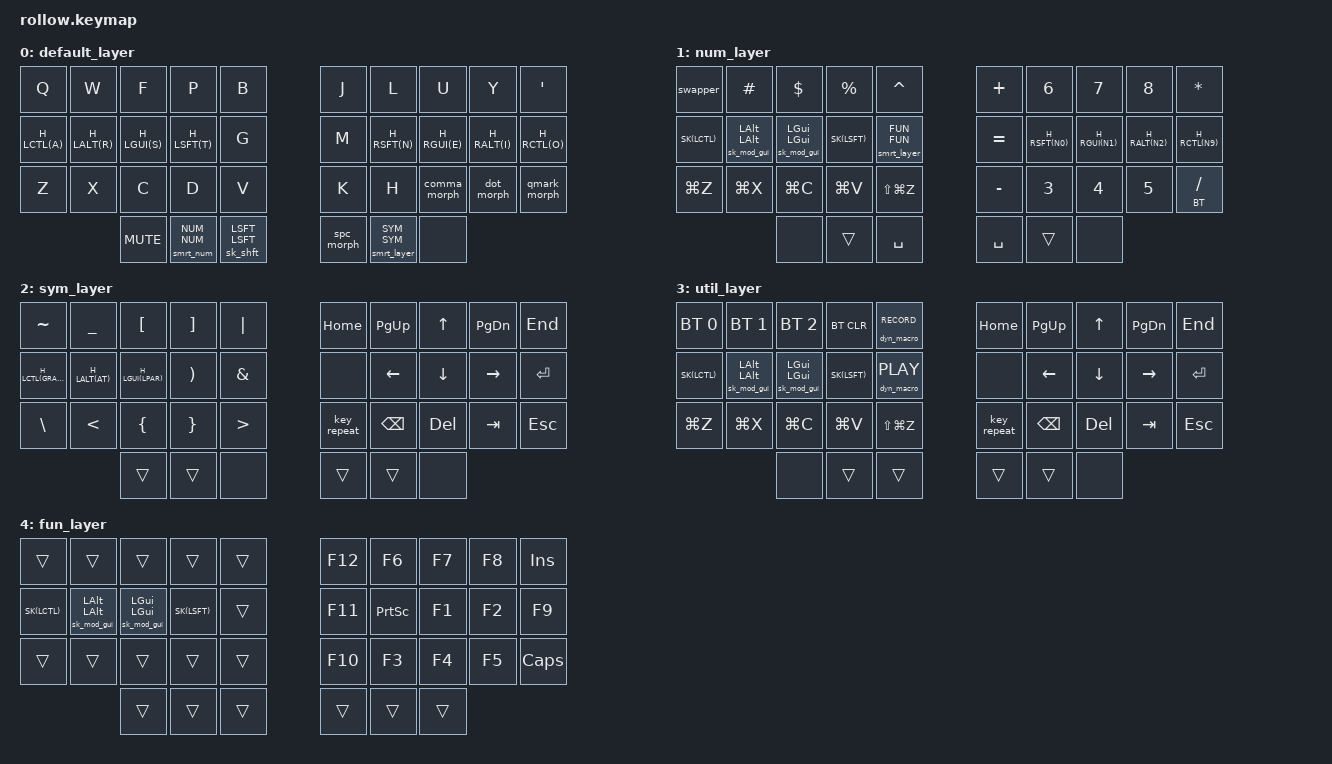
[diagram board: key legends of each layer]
// Copyright (c) 2022 The ZMK Contributors
// SPDX-License-Identifier: MIT

#include "../zmk-nodefree-config/helper.h"
#include "../zmk-nodefree-config/keypos_def/keypos_36keys.h"
#include <behaviors.dtsi>
#include <dt-bindings/zmk/keys.h>
#include <dt-bindings/zmk/bt.h>
#include <dt-bindings/zmk/dynamic-macros.h>

#define XXX &none
#define TODO XXX
#define ___ &trans

#define BASE 0
#define NUM 1
#define SYM 2
#define UTIL 3
#define FUN 4
#define BT 5

#define S_UNDO &kp LG(Z)
#define S_CUT &kp LG(X)
#define S_COPY &kp LG(C)
#define S_PASTE &kp LG(V)
#define S_REDO &kp LS(LG(Z))

/* ------------------------ general config ----------------------- */
// smart-layer config
&caps_word {  
    /delete-property/ ignore-modifiers; // mods deactivate, requires PR #1451
    /delete-property/ ignore-numbers;
    continue-list = <BACKSPACE ENTER DELETE UNDERSCORE MINUS>;
};
&num_word { 
    layers = <NUM>; // requires PR #1441
    continue-list = <BACKSPACE ENTER DELETE UNDERSCORE MINUS PLUS ASTRK EQUAL FSLH DOT LPAR RPAR HASH DLLR PRCNT CARET LEFT RIGHT UP DOWN>;
};

// key-repeat config
&key_repeat {
    usage-pages = <HID_USAGE_KEY HID_USAGE_CONSUMER>; // repeat all keys
};

// default layer-tap config
&lt {  
    flavor = "balanced";
    tapping-term-ms = <200>;
};

ZMK_CONDITIONAL_LAYER(NUM SYM, UTIL)

/* ---------------------------- special behaviors --------------------------- */
// Alt+Tab swapper, requires PR #1366
ZMK_BEHAVIOR(swapper, tri_state,
    bindings = <&kt LALT>, <&kp TAB>, <&kt LGUI>;
    ignored-key-positions = <LM1>; // shift-alt-tab 
)

// dynamci macros, requires PR #1351
ZMK_BEHAVIOR(dyn_macro, dynamic_macro, wait-ms = <10>;)

/* ------------------------------ home row mods ----------------------------- */
// #define KEYS_L LT0 LT1 LT2 LT3 LT4 LM0 LM1 LM2 LM3 LM4 LB0 LB1 LB2 LB3 LB4  // left hand
// #define KEYS_R RT0 RT1 RT2 RT3 RT4 RM0 RM1 RM2 RM3 RM4 RB0 RB1 RB2 RB3 RB4  // right hand
// #define THUMBS LH2 LH1 LH0 RH0 RH1 RH2                                      // thumbs

// // 280, 150
// #define MAKE_HRM(NAME, HOLD, TAP, TRIGGER_POS, EXTRA) \
//     ZMK_BEHAVIOR(NAME, hold_tap, \
//         flavor = "balanced"; \
//         tapping-term-ms = <500>; \
//         quick-tap-ms = <175>; \
//         global-quick-tap-ms = <150>; \
//         bindings = <HOLD>, <TAP>; \
//         hold-trigger-key-positions = <TRIGGER_POS>; \
//         hold-trigger-on-release; \
//         EXTRA \
//     )
// // TODO: potentially only space thumb
// MAKE_HRM(hmlg, &kp, &kp, KEYS_R THUMBS, )  // left-hand HRMs
// MAKE_HRM(hmrg, &kp, &kp, KEYS_L THUMBS, )  // right-hand HRMs
// MAKE_HRM(hml, &kp, &kp, KEYS_R THUMBS, hold-while-undecided;)  // left-hand HRMs
// MAKE_HRM(hmr, &kp, &kp, KEYS_L THUMBS, hold-while-undecided;)  // right-hand HRMs

#define H_LGUI(key) &kp key
#define H_LALT(key) &kp key
#define H_LCTL(key) &kp key
#define H_LSFT(key) &kp key
#define H_RSFT(key) &kp key
#define H_RCTL(key) &kp key
#define H_RALT(key) &kp key
#define H_RGUI(key) &kp key
// #define H_LGUI(key) &hmlg LGUI key 
// #define H_LALT(key) &hmlg LALT key 
// #define H_LCTL(key) &hml LCTL key
// #define H_LSFT(key) &hml LSFT key
// #define H_RSFT(key) &hmr RSFT key
// #define H_RCTL(key) &hmr RCTL key
// #define H_RALT(key) &hmrg RALT key
// #define H_RGUI(key) &hmrg RGUI key

/* --------------------------- sticky key behaviors -------------------------- */
// global config
&sk { // sticky-key
    release-after-ms = <3000>;  // release after timeout
    quick-release;              // no double capitalization when rolling ke
    ignore-modifiers;
    lazy;
};
ZMK_BEHAVIOR(sk_no_lazy, sticky_key, // sticky-key without lazy
    bindings = <&kp>;
    release-after-ms = <3000>;  // release after timeout
    quick-release;              // no double capitalization when rolling keys
    ignore-modifiers;
)
&sl { // sticky-layer 
    release-after-ms = <500>;  // release after timeout
    // This is useful for enabling a layer and then pressing a bunch of sticky keys without leaving the layer. 
    // However, this breaks tapping sl+control+key because it does not exit the layer.
    // ignore-modifiers;
};

// all sticky keys are sticky when tapped, but momentary when held. 
// this allows for rolling layer keys, and accessing modifiers on base, while not getting in the way.
// this behavior is especially useful for use with a mouse because sticky odifiers don't linger
#define STICKY_TAP_MS 200

// tap: sticky-mod | hold: mod
#define SK(mod) &sk_mod mod mod
ZMK_BEHAVIOR(sk_mod, hold_tap,
    flavor = "balanced"; // balanced because we want to consider as tap when rolling
    tapping-term-ms = <STICKY_TAP_MS>; 
    bindings = <&kp>, <&sk>; 
    hold-while-undecided; // requires pr
)
// for GUI/ALT, we don't want to trigger a tap, so we disable hold while undecided
#define SK_LGUI &sk_mod_gui LGUI LGUI 
#define SK_LALT &sk_mod_gui LALT LALT 
ZMK_BEHAVIOR(sk_mod_gui, hold_tap,
    flavor = "balanced"; // balanced because we want to consider as tap when rolling
    tapping-term-ms = <STICKY_TAP_MS>; 
    bindings = <&kp>, <&sk>; 
)

// tap: sticky-shift | hold: shift | shift + tap / double-tap: caps-word 
#define SK_SHFT &sk_shft LSFT LSFT
ZMK_BEHAVIOR(sk_shft, hold_tap,
    flavor = "balanced"; 
    tapping-term-ms = <STICKY_TAP_MS>; 
    bindings = <&kp>, <&smrt_shft_morph>; 
    hold-while-undecided;
) 
ZMK_BEHAVIOR(smrt_shft_morph, mod_morph,
    mods = <(MOD_LSFT)>; // shift + tap: caps word
    bindings = <&sk_no_lazy LSFT>, <&caps_word>; 
) 

// tap: sticky-layer | hold: layer
#define SMRT_SYM &smrt_layer SYM SYM
#define SMRT_FUN &smrt_layer FUN FUN
ZMK_BEHAVIOR(smrt_layer, hold_tap,
    flavor = "hold-preferred"; // in most cases we want to avoid taps
    tapping-term-ms = <STICKY_TAP_MS>; 
    bindings = <&mo>, <&sl>; 
) 

// tap: sticky-num | hold: num | double-tap: num-word | triple-tap: num-lock
#define SMRT_NUM &smrt_num NUM NUM
ZMK_BEHAVIOR(smrt_num, hold_tap,
    flavor = "hold-preferred"; 
    tapping-term-ms = <STICKY_TAP_MS>; 
    bindings = <&mo>, <&num_dance>; 
) 
ZMK_BEHAVIOR(num_dance, tap_dance,
    tapping-term-ms = <300>; 
    bindings = <&sl NUM>, <&num_word>, <&tog NUM>; // todo: to or tog?
)

/* ------------------------------- mod-morphs ------------------------------- */
// tap: comma | shift + tap: semicolon 
ZMK_BEHAVIOR(comma_morph, mod_morph,
    mods = <(MOD_LSFT|MOD_RSFT)>;
    bindings = <&kp COMMA>, <&kp SEMICOLON>;
)
// tap: dot | shift + tap: colon 
ZMK_BEHAVIOR(dot_morph, mod_morph,
    bindings = <&kp DOT>, <&kp COLON>;
    mods = <(MOD_LSFT|MOD_RSFT)>;
)
// tap: qmark | shift + tap: excl
ZMK_BEHAVIOR(qmark_morph, mod_morph,
    bindings = <&kp QMARK>, <&kp EXCL>;
    mods = <(MOD_LSFT|MOD_RSFT)>;
)

// tap: space | shift + tap: dot -> space -> sticky shift
ZMK_BEHAVIOR(spc_morph, mod_morph,
    bindings = <&kp SPACE>, <&dot_spc>;
    mods = <(MOD_LSFT|MOD_RSFT)>;
)
ZMK_BEHAVIOR(dot_spc, macro,
    wait-ms = <5>;
    tap-ms = <5>;
    bindings = <&dot_morph_cancel &kp SPACE &sk LSFT>;
)
ZMK_BEHAVIOR(dot_morph_cancel, mod_morph,
    bindings = <&kp DOT>, <&kp DOT>;
    mods = <(MOD_LSFT|MOD_RSFT)>;
)

/ {
    chosen {
        zmk,matrix_transform = &five_column_transform;
    };

    keymap {
        compatible = "zmk,keymap";
        default_layer { // ColemakDHm
            bindings = <
            &kp Q     &kp W     &kp F     &kp P     &kp B     &kp J       &kp L     &kp U        &kp Y      &kp APOS 
            H_LCTL(A) H_LALT(R) H_LGUI(S) H_LSFT(T) &kp G     &kp M       H_RSFT(N) H_RGUI(E)    H_RALT(I)  H_RCTL(O) 
            &kp Z     &kp X     &kp C     &kp D     &kp V     &kp K       &kp H     &comma_morph &dot_morph &qmark_morph
                                &kp C_MUTE SMRT_NUM SK_SHFT   &spc_morph  SMRT_SYM  XXX 
            >;
        };
        num_layer {
            bindings = <
            &swapper  &kp HASH  &kp DLLR   &kp PRCNT  &kp CARET   &kp PLUS  &kp N6     &kp N7     &kp N8     &kp ASTRK 
            SK(LCTL)   SK_LALT   SK_LGUI   SK(LSFT)   SMRT_FUN    &kp EQUAL H_RSFT(N0) H_RGUI(N1) H_RALT(N2) H_RCTL(N9) 
            S_UNDO    S_CUT     S_COPY     S_PASTE    S_REDO      &kp MINUS &kp N3     &kp N4     &kp N5     &lt BT FSLH 
                                XXX        ___        &kp SPACE   &kp SPACE ___        XXX 
            >;
        };
        sym_layer {
            bindings = <
            &kp TILDE     &kp UNDER   &kp LBKT      &kp RBKT  &kp PIPE      &kp HOME    &kp PG_UP  &kp UP     &kp PG_DN  &kp END
            H_LCTL(GRAVE) H_LALT(AT)  H_LGUI(LPAR)  &kp RPAR  &kp AMPS      XXX         &kp LEFT   &kp DOWN   &kp RIGHT  &kp ENTER 
            &kp BSLH      &kp LT      &kp LBRC      &kp RBRC  &kp GT        &key_repeat &kp BSPC   &kp DEL    &kp TAB    &kp ESC 
                                      ___           ___       XXX           ___         ___        XXX 
            >;
        };
 
        util_layer {
            bindings = <
            &bt BT_SEL 0 &bt BT_SEL 1 &bt BT_SEL 2 &bt BT_CLR  &dyn_macro RECORD  &kp HOME     &kp PG_UP  &kp UP    &kp PG_DN  &kp END
            SK(LCTL)      SK_LALT      SK_LGUI     SK(LSFT)    &dyn_macro PLAY    XXX          &kp LEFT   &kp DOWN  &kp RIGHT  &kp ENTER 
            S_UNDO       S_CUT        S_COPY       S_PASTE     S_REDO             &key_repeat  &kp BSPC   &kp DEL   &kp TAB    &kp ESC 
                                      XXX          ___         ___                ___          ___        XXX 
            >;
        };

        fun_layer {
            bindings = <
            ___       ___       ___        ___        ___    &kp F12  &kp F6     &kp F7  &kp F8  &kp INSERT
            SK(LCTL)   SK_LALT   SK_LGUI   SK(LSFT)   ___    &kp F11  &kp PSCRN  &kp F1  &kp F2  &kp F9
            ___       ___       ___        ___        ___    &kp F10  &kp F3     &kp F4  &kp F5  &kp CAPS
                                ___        ___        ___    ___      ___        ___ 
            >;
        };
    };
};
    
/* --------------------------------- combos --------------------------------- */
// ╭─────────────────────┬─────────────────────╮
// │ LT4 LT3 LT2 LT1 LT0 │ RT0 RT1 RT2 RT3 RT4 │
// │ LM4 LM3 LM2 LM1 LM0 │ RM0 RM1 RM2 RM3 RM4 │
// │ LB4 LB3 LB2 LB1 LB0 │ RB0 RB1 RB2 RB3 RB4 │
// ╰───────╮ LH2 LH1 LH0 │ RH0 RH1 RH2 ╭───────╯
//         ╰─────────────┴─────────────╯
// use global-quick-tap-ms for combos (requires PR 1387)
#undef COMBO_HOOK
#define COMBO_HOOK global-quick-tap-ms = <50>;
// combos on every layer
#define LAYER_COMBO(name, keypos, bindings, layer) ZMK_COMBO(name, bindings, keypos, layer, 50)
#define GLOBAL_COMBO(name, keypos, bindings) LAYER_COMBO(name, keypos, bindings, ALL)
// GLOBAL_COMBO(bksp, RB1 RB2, &kp BSPC)
// GLOBAL_COMBO(del, RB2 RB3, &kp DEL)
GLOBAL_COMBO(numl, RB3 RB4, &num_word)
GLOBAL_COMBO(dot_spc, LH0 RH0, &dot_spc)

// combos on the numpad
#define NUM_COMBO(name, keypos, bindings) ZMK_COMBO(name, bindings, keypos, NUM, 40)
NUM_COMBO(dot, RM0 RM1, &kp DOT)
NUM_COMBO(esc, LT3 LT2, &kp ESC)
NUM_COMBO(tab, LT2 LT1, &kp TAB)
NUM_COMBO(gui, LB3 LB2, &kp LGUI)
NUM_COMBO(ent, LB2 LB1, &kp ENTER)
NUM_COMBO(lpar, LT2 LM2, &kp LPAR)
NUM_COMBO(rpar, LT1 LM1, &kp RPAR)
NUM_COMBO(x, LM3 LB3, &kp X)

// vertical sfb combos
#define VERTICAL_COMBO(keypos, key1, key2) \
    ZMK_BEHAVIOR(macro_vertical_combo_##key1##key2, macro, \
        wait-ms = <20>; \
        tap-ms = <20>; \
        bindings \
            = <&macro_tap &kp key1> \
            , <&macro_press &kp key2> \
            , <&macro_pause_for_release> \
            , <&macro_release &kp key2> \
            ; \
    ) \
    / { \
        combos { \
            compatible = "zmk,combos"; \
            combo_vertical_combo_##key1##key2 { \
                timeout-ms = <40>; \
                layers = <BASE>; \
                key-positions = <keypos>; \
                bindings = <&macro_vertical_combo_##key1##key2>; \
                slow-release;  \
            }; \
        }; \
    };

// disambiguate mashing SFBs
// this is the only one relevant to Colemak layout
/* VERTICAL_COMBO(LT3 LM3, R, L) */
/* VERTICAL_COMBO(LT1 LM1, W, S) */
VERTICAL_COMBO(LM2 LB2, S, C)
/* VERTICAL_COMBO(LM1 LM0, G, S) */
/* VERTICAL_COMBO(RM1 RM0, H, Y) */
/* VERTICAL_COMBO(RM1 RB1, P, H) */
/* VERTICAL_COMBO(RT2 RM2, O, A) */
/* VERTICAL_COMBO(RM0 RT0, Y, APOS) */
/* VERTICAL_COMBO(RM4 RT0, I, APOS) */

// ANACRON COMBOS
// the macro is used to enable the layer while the combo is held so that other keys
// on the layer can be used while the thumb is still held
#define THUMB_COMBO_GENERAL(thumb_behavior, thumb_param, thumb, combo_layers, keypos, combo_bindings) \
    ZMK_BEHAVIOR(macro_thumb_##thumb_param##_##thumb##_##keypos, macro, \
        wait-ms = <0>; \
        tap-ms = <0>; \
        bindings \
            = <&macro_press thumb_behavior thumb_param> \
            , <&macro_press combo_bindings> \
            , <&macro_pause_for_release> \
            , <&macro_release combo_bindings> \
            , <&macro_release thumb_behavior thumb_param> \
            ; \
    ) \
    / { \
        combos { \
            compatible = "zmk,combos"; \
            combo_thumb_##thumb_param##_##thumb##_##keypos { \
                timeout-ms = <40>; \
                layers = <combo_layers>; \
                key-positions = <thumb keypos>; \
                bindings = <&macro_thumb_##thumb_param##_##thumb##_##keypos>, <&partial_hold_position thumb thumb_behavior thumb_param>; \
                slow-release;  \
                slow-release-positions = <keypos>; \
                COMBO_HOOK \
            }; \
        }; \
    };
#define THUMB_LAYER_COMBO(thumb_param, thumb, combo_layers, keypos, combo_bindings) THUMB_COMBO_GENERAL(&mo, thumb_param, thumb, combo_layers, keypos, combo_bindings)

// right thumb combos with right hand SYM layer
#define SYM_THUMB_COMBO(keypos, bindings) THUMB_LAYER_COMBO(SYM, RH1, BASE NUM, keypos, bindings)
SYM_THUMB_COMBO(RT0, &kp HOME)
SYM_THUMB_COMBO(RT1, &kp PG_UP)
SYM_THUMB_COMBO(RT2, &kp UP)
SYM_THUMB_COMBO(RT3, &kp PG_DN)
SYM_THUMB_COMBO(RT4, &kp END)
//SYM_THUMB_COMBO(RM0, XXX)
SYM_THUMB_COMBO(RM1, &kp LEFT)
SYM_THUMB_COMBO(RM2, &kp DOWN)
SYM_THUMB_COMBO(RM3, &kp RIGHT)
SYM_THUMB_COMBO(RM4, &kp ENTER)
SYM_THUMB_COMBO(RB0, &key_repeat) 
SYM_THUMB_COMBO(RB1, &kp BSPC)
SYM_THUMB_COMBO(RB2, &kp DEL)
SYM_THUMB_COMBO(RB3, &kp TAB)
SYM_THUMB_COMBO(RB4, &kp ESC)

// right thumb combos with left hand SYM layer 
#define SYM_THUMB_CROSS_COMBO(keypos, bindings) THUMB_LAYER_COMBO(SYM, RH1, BASE, keypos, bindings)
SYM_THUMB_CROSS_COMBO(LT4, &kp TILDE)
SYM_THUMB_CROSS_COMBO(LT3, &kp PIPE)
SYM_THUMB_CROSS_COMBO(LT2, &kp UNDER)
SYM_THUMB_CROSS_COMBO(LT1, &kp LBKT)
SYM_THUMB_CROSS_COMBO(LT0, &kp RBKT)
SYM_THUMB_CROSS_COMBO(LM4, &kp GRAVE)
SYM_THUMB_CROSS_COMBO(LM3, &kp AMPS)
SYM_THUMB_CROSS_COMBO(LM2, &kp AT)
SYM_THUMB_CROSS_COMBO(LM1, &kp LPAR)
SYM_THUMB_CROSS_COMBO(LM0, &kp RPAR)
SYM_THUMB_CROSS_COMBO(LB4, &kp BSLH)
SYM_THUMB_CROSS_COMBO(LB3, &kp LT)
SYM_THUMB_CROSS_COMBO(LB2, &kp GT)
SYM_THUMB_CROSS_COMBO(LB1, &kp LBRC)
SYM_THUMB_CROSS_COMBO(LB0, &kp RBRC)

// left thumb combos with left hand NUM layer
#define NUM_THUMB_COMBO(keypos, bindings) THUMB_LAYER_COMBO(NUM, LH1, BASE SYM, keypos, bindings)
NUM_THUMB_COMBO(LT4, &swapper)
NUM_THUMB_COMBO(LT3, &kp HASH)
NUM_THUMB_COMBO(LT2, &kp DLLR)
NUM_THUMB_COMBO(LT1, &kp PRCNT)
NUM_THUMB_COMBO(LT0, &kp CARET)
NUM_THUMB_COMBO(LM4, SK(LCTL))
NUM_THUMB_COMBO(LM3, SK_LALT)
NUM_THUMB_COMBO(LM2, SK_LGUI)
NUM_THUMB_COMBO(LM1, SK(LSFT))
NUM_THUMB_COMBO(LM0, SMRT_FUN)
NUM_THUMB_COMBO(LB4, S_UNDO)
NUM_THUMB_COMBO(LB3, S_CUT)
NUM_THUMB_COMBO(LB2, S_COPY)
NUM_THUMB_COMBO(LB1, S_PASTE)
NUM_THUMB_COMBO(LB0, S_REDO)

// left thumb combos with right hand NUM layer
#define NUM_THUMB_CROSS_COMBO(keypos, bindings) THUMB_LAYER_COMBO(NUM, LH1, BASE, keypos, bindings)
NUM_THUMB_CROSS_COMBO(RT0, &kp PLUS)
NUM_THUMB_CROSS_COMBO(RT1, &kp N6)
NUM_THUMB_CROSS_COMBO(RT2, &kp N7)
NUM_THUMB_CROSS_COMBO(RT3, &kp N8)
NUM_THUMB_CROSS_COMBO(RT4, &kp ASTRK)
NUM_THUMB_CROSS_COMBO(RM0, &kp EQUAL)
NUM_THUMB_CROSS_COMBO(RM1, &kp N0)
NUM_THUMB_CROSS_COMBO(RM2, &kp N1)
NUM_THUMB_CROSS_COMBO(RM3, &kp N2)
NUM_THUMB_CROSS_COMBO(RM4, &kp N9)
NUM_THUMB_CROSS_COMBO(RB0, &kp MINUS)
NUM_THUMB_CROSS_COMBO(RB1, &kp N3)
NUM_THUMB_CROSS_COMBO(RB2, &kp N4)
NUM_THUMB_CROSS_COMBO(RB3, &kp N5)
NUM_THUMB_CROSS_COMBO(RB4, &kp SLASH)

// left thumb combos with both hands BASE layer
#define SHFT_THUMB_COMBO(keypos, bindings) THUMB_COMBO_GENERAL(&kp, LSFT, LH0, BASE, keypos, bindings)
SHFT_THUMB_COMBO(LT4, &kp Q)
SHFT_THUMB_COMBO(LT3, &kp W)
SHFT_THUMB_COMBO(LT2, &kp F)
SHFT_THUMB_COMBO(LT1, &kp P)
SHFT_THUMB_COMBO(LT0, &kp B)
SHFT_THUMB_COMBO(LM4, &kp A)
SHFT_THUMB_COMBO(LM3, &kp R)
SHFT_THUMB_COMBO(LM2, &kp S)
SHFT_THUMB_COMBO(LM1, &kp T)
SHFT_THUMB_COMBO(LM0, &kp G)
SHFT_THUMB_COMBO(LB4, &kp Z)
SHFT_THUMB_COMBO(LB3, &kp X)
SHFT_THUMB_COMBO(LB2, &kp C)
SHFT_THUMB_COMBO(LB1, &kp D)
SHFT_THUMB_COMBO(LB0, &kp V)

SHFT_THUMB_COMBO(RT0, &kp J)
SHFT_THUMB_COMBO(RT1, &kp L)
SHFT_THUMB_COMBO(RT2, &kp U)
SHFT_THUMB_COMBO(RT3, &kp Y)
SHFT_THUMB_COMBO(RT4, &kp APOS)
SHFT_THUMB_COMBO(RM0, &kp M)
SHFT_THUMB_COMBO(RM1, &kp N)
SHFT_THUMB_COMBO(RM2, &kp E)
SHFT_THUMB_COMBO(RM3, &kp I)
SHFT_THUMB_COMBO(RM4, &kp O)
SHFT_THUMB_COMBO(RB0, &kp K)
SHFT_THUMB_COMBO(RB1, &kp H)
SHFT_THUMB_COMBO(RB2, &comma_morph)
SHFT_THUMB_COMBO(RB3, &dot_morph)
SHFT_THUMB_COMBO(RB4, &qmark_morph)

// TODO:
// - Hardware:
//   - fix right encoder
//   - Fix left OLED
// - Conceptual:
//   - Consider mouse layer
//   - Investigate media keys (brightness, display toggle, music)
// - Minor:
//   - Caps word timeout
//   - Fix undo/redo
//   - Hold symbol for double/triple tap?
// - Workflow:
//   - Add text expansion macros
//   - Add programming bigrams
//   - Investigate symbol sfbs. 
//   - Caps word invert shift
// - ZMK:
//   - bug: sticky cancel releases mo layer

// what if re-add CANCEL on mo tap, but only on layer. Motivation, cancel num lock/caps word. Want to tap sym to cancel. 
// caps kebab, double space ends word

// https://getreuer.info/posts/keyboards/select-word/index.html
// maybe patch tap dance to trigger on every tap
